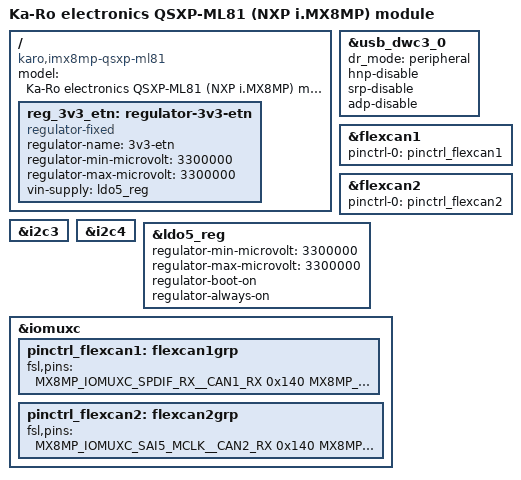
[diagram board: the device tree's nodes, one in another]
// SPDX-License-Identifier: (GPL-2.0 OR MIT)
/*
 * Copyright (C) 2020 Lothar Waßmann <LW@KARO-electronics.de>
 *
 */

/dts-v1/;

#include "imx8mp-karo.dtsi"

/ {
	model = "Ka-Ro electronics QSXP-ML81 (NXP i.MX8MP) module";
	compatible = "karo,imx8mp-qsxp-ml81", "fsl,imx8mp";

	reg_3v3_etn: regulator-3v3-etn {
		compatible = "regulator-fixed";
		regulator-name = "3v3-etn";
		regulator-min-microvolt = <3300000>;
		regulator-max-microvolt = <3300000>;
		vin-supply = <&ldo5_reg>;
	};
};

&usb_dwc3_0 {
	dr_mode = "peripheral";
	hnp-disable;
	srp-disable;
	adp-disable;
	status = "okay";
};

&flexcan1 {
	pinctrl-names = "default";
	pinctrl-0 = <&pinctrl_flexcan1>;
};

&flexcan2 {
	pinctrl-names = "default";
	pinctrl-0 = <&pinctrl_flexcan2>;
};

&i2c3 {
	status = "okay";
};

&i2c4 {
	status = "okay";
};

&ldo5_reg {
	regulator-min-microvolt = <3300000>;
	regulator-max-microvolt = <3300000>;
	regulator-boot-on;
	regulator-always-on;
};

&iomuxc {
	pinctrl_flexcan1: flexcan1grp {
		fsl,pins = <
			MX8MP_IOMUXC_SPDIF_RX__CAN1_RX 0x140
			MX8MP_IOMUXC_SPDIF_TX__CAN1_TX 0x140
		>;
	};

	pinctrl_flexcan2: flexcan2grp {
		fsl,pins = <
			MX8MP_IOMUXC_SAI5_MCLK__CAN2_RX 0x140
			MX8MP_IOMUXC_SAI5_RXD3__CAN2_TX 0x140
		>;
	};
};
